# MDR32F8 register map
Vendor: Milandr; File version: 1.0
CPU: CM4 r1p1, little endian, no MPU, no FPU, 3 interrupt priority bits
Registers are 32-bit, read-write, reset 0x0 unless marked. A register's access mark holds for its fields unless they carry their own. Offsets are from the block's base; lines under a group give offsets from that group; [hi:lo] are bit positions; {n}, {i} and the like mark numbered series; 'fields as' and 'values as' point back to an identical list; <NAME> marks a mode.

## Memory map
0x21000000 MDR_ETH size 0x1000 — Ethernet
0x40000000 MDR_CLK size 0x1000 — Clock controll registers
0x40001000 MDR_BKP size 0x1000 — BACKUP
0x40002000 MDR_POWER size 0x1000 — POWER
0x40003000 FT_CNTR size 0x88 — Fault Tolerance Control
0x40004000 MDR_WDT size 0x10 — Watch Dog Timer
0x40005000 MDR_EBC size 0x88 — External Bus Control
0x40006000 MDR_OTP size 0x28 — OTP Memory Control
0x40008000 MDR_RAMD size 0x18 — RAMD Control
0x40009000 MDR_ROM size 0x18 — ROM Control
0x4000B000 MDR_SCACHE size 0x30 — S-BUS Cache Controller
0x40080000 MDR_PORTA size 0x8C — PORTA
0x40081000 MDR_PORTB size 0x8C — PORTB
0x40082000 MDR_PORTC size 0x8C — PORTC
0x40083000 MDR_PORTD size 0x8C — PORTD
0x40084000 MDR_PORTE size 0x8C — PORTE
0x40088000 MDR_SPW size 0x1000 — SPW controller
0x4008A000 TIMER0 size 0x1000
0x4008B000 TIMER1 size 0x1000
0x4008C000 TIMER2 size 0x1000
0x4008D000 TIMER3 size 0x1000
0x40090000 MDR_CAN size 0x1000 — CAN interfase controller registers
0x40095000 MDR_SSP size 0x1000 — SSP interfase controller registers
0x40099000 UART0 size 0x1000 — UART0 interfase controller registers
0x4009A000 UART1 size 0x1000 — UART1 interfase controller registers
0x4009E000 ARINC429R size 0x1000 — ARINC429 Receive Controller
0x4009F000 ARINC429R_DATA size 0x1000 — ARINC429 Receive DATA
0x400A0000 ARINC429T size 0x1000 — ARINC429 Transive Controller
0x400A1000 ARINC429T_DATA size 0x1000 — ARINC429 Transive DATA
0x400A6000 MDR_MILDAT_15530 size 0x1000 — MIL_DATA
0x400A7000 MDR_MIL_STD_15530 size 0x1000 — MIL_STD_1553 interfase controller registers
0x400A8000 MDR_MILDAT_15531 size 0x1000 — MIL_DATA
0x400A9000 MDR_MIL_STD_15531 size 0x1000 — MIL_STD_1553 interfase controller registers
0x400AA000 ADC0 size 0x1000 — ADC
0x400AB000 ADC1 size 0x1000 — ADC
0x400AC000 DAC0 size 0x1000 — DAC
0x400AD000 DAC1 size 0x1000 — DAC
0xE0042000 MDR_DMA size 0x1000 — DMA controller registers
0xE0044000 MDR_ICACHE size 0x30 — I-BUS Cache Controller
0xE0045000 MDR_DCACHE size 0x30 — D-BUS Cache Controller

## Interrupts
15 NOP_INTR (MDR_ETH)
32 FT_IF0 (FT_CNTR)
33 FT_IF1 (FT_CNTR)
34 FT_IF2 (FT_CNTR)
35 FT_IF3 (FT_CNTR)
36 CLK_IF (MDR_CLK)
37 PVD_IF (MDR_POWER)
38 RTC_IF (MDR_BKP)
39 BKP_IF (MDR_BKP)
{n+40} EXT_INTERROR{n} (MDR_EBC) (n=0..7)
50 DMA_ERR (MDR_DMA)
{n+51} DMA_DONE{n} (MDR_DMA) (n=0..31)
83 IRQ_PORTA (MDR_PORTA)
84 IRQ_PORTB (MDR_PORTB)
85 IRQ_PORTC (MDR_PORTC)
86 IRQ_PORTD (MDR_PORTD)
87 IRQ_PORTE (MDR_PORTE)
89 INT_ETH (MDR_ETH)
91 INT_SPW (MDR_SPW)
93 INT_TMR0 (TIMER0)
94 INT_TMR1 (TIMER1)
95 INT_TMR2 (TIMER2)
96 INT_TMR3 (TIMER3)
99 INT_CAN (MDR_CAN)
104 INT_SSP (MDR_SSP)
108 INT_UART0 (UART0)
109 INT_UART1 (UART1)
113 INT_RX_ARC (ARINC429R)
114 INT_TX_ARC (ARINC429T)
117 INT_MIL0 (MDR_MIL_STD_15530)
118 INT_MIL1 (MDR_MIL_STD_15531)
119 INT_ADC0 (ADC0)
120 INT_ADC1 (ADC1)
121 INT_DAC0 (DAC0)
122 INT_DAC1 (DAC1)

## MDR_BKP — BACKUP
Base 0x40001000
{0x0+4i} REG_{i:02} (i=0..59) — Backup Register {i}
  [31:0] DATA
0xF0 KEY — Key lock Register
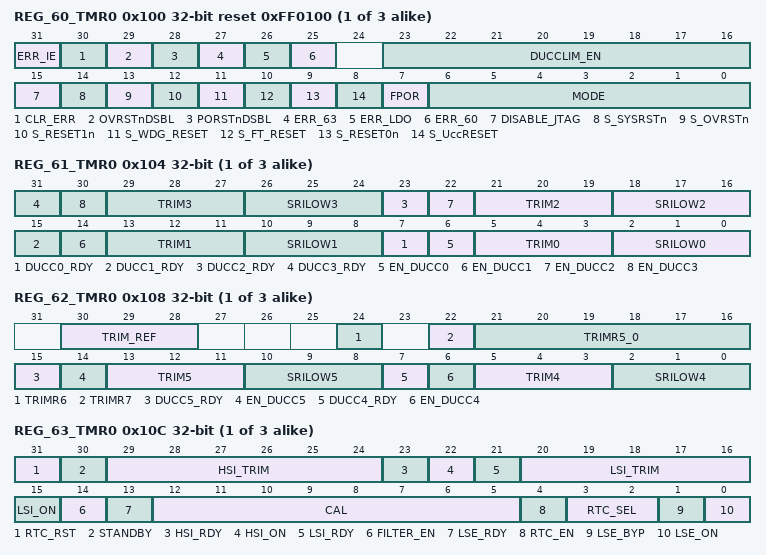
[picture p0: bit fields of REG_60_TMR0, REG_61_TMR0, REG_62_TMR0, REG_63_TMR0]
{0x100+0x10*i} REG_60_TMR{i} reset 0xFF0100 (i=0..2) — Backup Register 60_TMR{i}
  [31] ERR_IE, [30] CLR_ERR, [29] OVRSTnDSBL, [28] PORSTnDSBL, [27] ERR_63, [26] ERR_LDO, [25] ERR_60, [23:16] DUCCLIM_EN, [15] DISABLE_JTAG, [14] S_SYSRSTn, [13] S_OVRSTn, [12] S_RESET1n, [11] S_WDG_RESET, [10] S_FT_RESET, [9] S_RESET0n, [8] S_UccRESET, [7] FPOR, [6:0] MODE
{0x104+0x10*i} REG_61_TMR{i} (i=0..2) — Backup Register 61_TMR{i}
  [8n+7] DUCC{n}_RDY (n=0..3), [8n+6] EN_DUCC{n} (n=0..3), [8n+5:8n+3] TRIM{n} (n=0..3), [8n+2:8n] SRILOW{n} (n=0..3)
{0x108+0x10*i} REG_62_TMR{i} (i=0..2) — Backup Register 62_TMR{i}
  [30:28] TRIM_REF, [24] TRIMR6, [22] TRIMR7, [21:16] TRIMR5_0, [15] DUCC5_RDY, [14] EN_DUCC5, [13:11] TRIM5, [10:8] SRILOW5, [7] DUCC4_RDY, [6] EN_DUCC4, [5:3] TRIM4, [2:0] SRILOW4
{0x10C+0x10*i} REG_63_TMR{i} (i=0..2) — Backup Register 63_TMR{i}
  [31] RTC_RST, [30] STANDBY, [29:24] HSI_TRIM, [23] HSI_RDY, [22] HSI_ON, [21] LSI_RDY ro, [20:16] LSI_TRIM, [15] LSI_ON, [14] FILTER_EN, [13] LSE_RDY ro, [12:5] CAL, [4] RTC_EN, [3:2] RTC_SEL, [1] LSE_BYP, [0] LSE_ON
{0x130+0x20*i} RTC_CNT_TMR{i} (i=0..2) — Realtime Clock Counter Register
  [31:0] RTC_CNT
{0x134+0x20*i} RTC_DIV_TMR{i} (i=0..2) — Realtime Prescaler Counter Register
  [19:0] RTC_DIV
{0x138+0x20*i} RTC_PRL_TMR{i} (i=0..2) — Realtime Prescaler Auto-Reload Value Register
  [19:0] RTC_PRL
{0x13C+0x20*i} RTC_ALRM_TMR{i} (i=0..2) — Realtime Alarm Register
  [31:0] RTC_ALRM
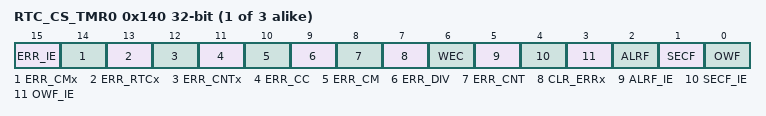
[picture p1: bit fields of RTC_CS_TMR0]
{0x140+0x20*i} RTC_CS_TMR{i} (i=0..2) — Backup Realtime clock Register
  [15] ERR_IE, [14] ERR_CMx, [13] ERR_RTCx, [12] ERR_CNTx, [11] ERR_CC, [10] ERR_CM, [9] ERR_DIV, [8] ERR_CNT, [7] CLR_ERRx, [6] WEC, [5] ALRF_IE, [4] SECF_IE, [3] OWF_IE, [2] ALRF, [1] SECF, [0] OWF
